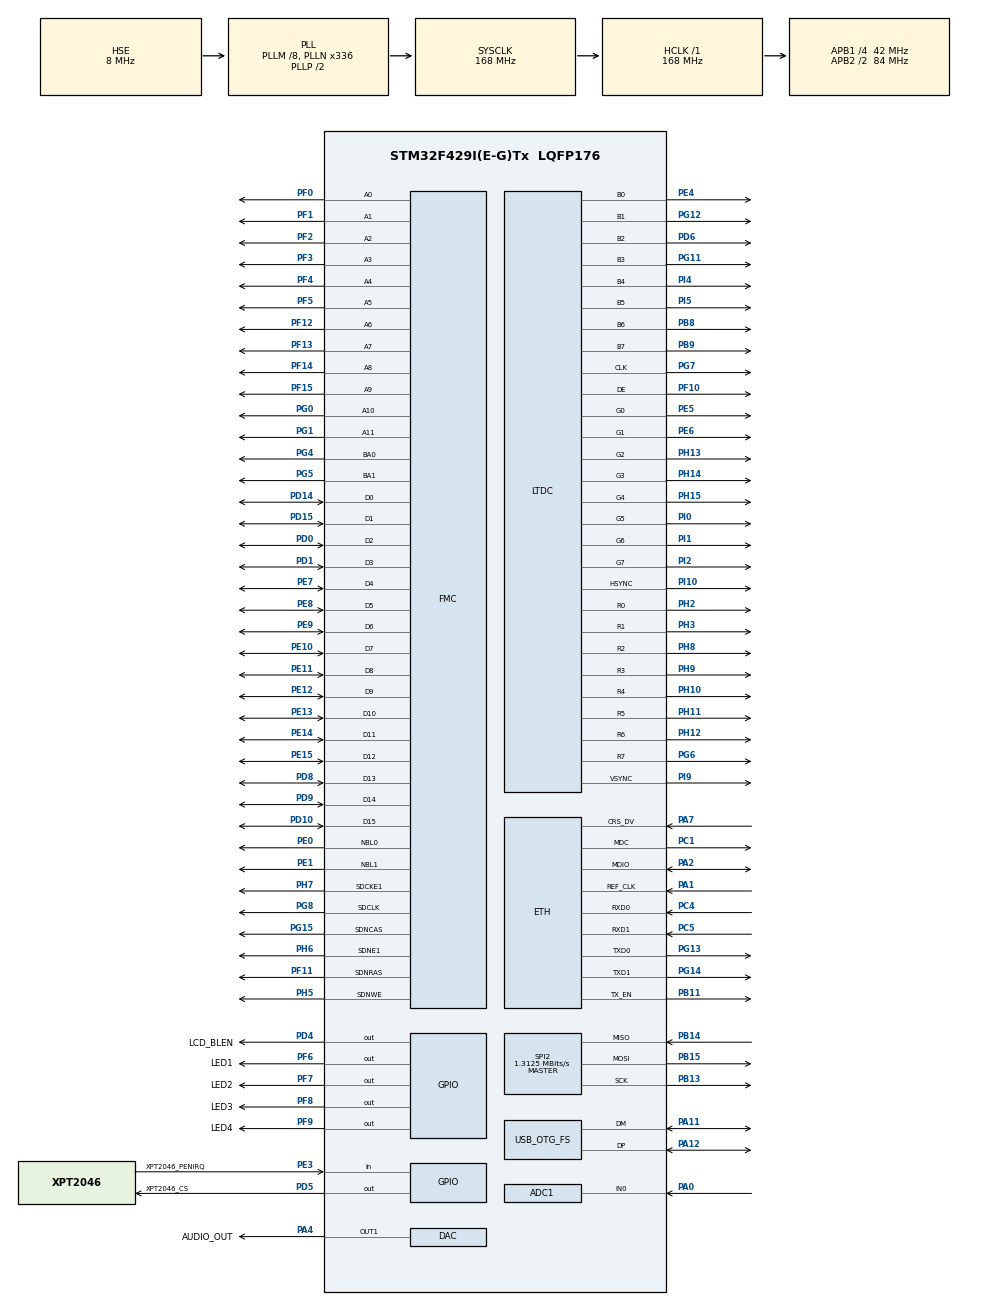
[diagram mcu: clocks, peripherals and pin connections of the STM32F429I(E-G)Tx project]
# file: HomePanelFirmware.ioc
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ADC1.Channel-0\#ChannelRegularConversion=ADC_CHANNEL_0
ADC1.ClockPrescaler=ADC_CLOCK_SYNC_PCLK_DIV4
ADC1.ContinuousConvMode=DISABLE
ADC1.DMAContinuousRequests=ENABLE
ADC1.DataAlign=ADC_DATAALIGN_LEFT
ADC1.DiscontinuousConvMode=DISABLE
ADC1.EOCSelection=ADC_EOC_SEQ_CONV
ADC1.EnableAnalogWatchDog=false
ADC1.ExternalTrigConv=ADC_EXTERNALTRIGCONV_T2_TRGO
ADC1.ExternalTrigConvEdge=ADC_EXTERNALTRIGCONVEDGE_RISING
ADC1.InjNumberOfConversion=0
ADC1.NbrOfConversion=1
ADC1.NbrOfConversionFlag=1
ADC1.Rank-0\#ChannelRegularConversion=1
ADC1.Resolution=ADC_RESOLUTION_12B
ADC1.SamplingTime-0\#ChannelRegularConversion=ADC_SAMPLETIME_15CYCLES
ADC1.ScanConvMode=DISABLE
ADC1.master=1
DAC.DAC_Trigger=DAC_TRIGGER_T2_TRGO
Dma.ADC1.1.Direction=DMA_PERIPH_TO_MEMORY
Dma.ADC1.1.FIFOMode=DMA_FIFOMODE_DISABLE
Dma.ADC1.1.Instance=DMA2_Stream0
Dma.ADC1.1.MemDataAlignment=DMA_MDATAALIGN_HALFWORD
Dma.ADC1.1.MemInc=DMA_MINC_ENABLE
Dma.ADC1.1.Mode=DMA_CIRCULAR
Dma.ADC1.1.PeriphDataAlignment=DMA_PDATAALIGN_HALFWORD
Dma.ADC1.1.PeriphInc=DMA_PINC_DISABLE
Dma.ADC1.1.Priority=DMA_PRIORITY_HIGH
Dma.DAC1.0.Direction=DMA_MEMORY_TO_PERIPH
Dma.DAC1.0.FIFOMode=DMA_FIFOMODE_DISABLE
Dma.DAC1.0.Instance=DMA1_Stream5
Dma.DAC1.0.MemDataAlignment=DMA_MDATAALIGN_HALFWORD
Dma.DAC1.0.MemInc=DMA_MINC_ENABLE
Dma.DAC1.0.Mode=DMA_CIRCULAR
Dma.DAC1.0.PeriphDataAlignment=DMA_PDATAALIGN_HALFWORD
Dma.DAC1.0.PeriphInc=DMA_PINC_DISABLE
Dma.DAC1.0.Priority=DMA_PRIORITY_HIGH
Dma.Request0=DAC1
Dma.Request1=ADC1
ETH.MACAddr=00\:80\:E4\:00\:00\:00
ETH.MediaInterface=ETH_MEDIA_INTERFACE_RMII
ETH.PHY_ISFR=0x0012
ETH.PHY_ISFR_INT4=0x0020
ETH.PHY_Name_RMII=LAN8742A_PHY_ADDRESS
FMC.CASLatency1=FMC_SDRAM_CAS_LATENCY_3
FMC.ExitSelfRefreshDelay1=10
FMC.LoadToActiveDelay1=2
FMC.RCDDelay1=2
FMC.RPDelay1=2
FMC.RPDelay2=2
FMC.ReadBurst1=FMC_SDRAM_RBURST_ENABLE
FMC.ReadBurst2=FMC_SDRAM_RBURST_ENABLE
FMC.ReadPipeDelay1=FMC_SDRAM_RPIPE_DELAY_2
FMC.ReadPipeDelay2=FMC_SDRAM_RPIPE_DELAY_2
FMC.RowCycleDelay1=6
FMC.RowCycleDelay2=6
FMC.SDClockPeriod1=FMC_SDRAM_CLOCK_PERIOD_2
FMC.SDClockPeriod2=FMC_SDRAM_CLOCK_PERIOD_2
FMC.SelfRefreshTime1=7
FMC.WriteRecoveryTime1=5
FREERTOS.Tasks01=defaultTask,0,128,StartDefaultTask,Default,NULL,Dynamic,NULL,NULL
FREERTOS.configGENERATE_RUN_TIME_STATS=0
FREERTOS.configTOTAL_HEAP_SIZE=70000
FREERTOS.configUSE_COUNTING_SEMAPHORES=1
FREERTOS.configUSE_STATS_FORMATTING_FUNCTIONS=1
FREERTOS.configUSE_TIMERS=1
FREERTOS.configUSE_TRACE_FACILITY=1
LTDC.ActiveH=272
LTDC.ActiveW=480
LTDC.Alpha0_L0=255
LTDC.Alpha_L0=255
LTDC.FBStartAdress_L0=0xD0000000
LTDC.Green=255
LTDC.HBP=2
LTDC.HFP=2
LTDC.HSync=41
LTDC.ImageHeight_L0=272
LTDC.ImageWidth_L0=480
LTDC.Layers=0
LTDC.VSync=10
LTDC.WindowX1_L0=480
LTDC.WindowY1_L0=272
LWIP.LWIP_DHCP_CHECK_LINK_UP=1
LWIP.LWIP_IGMP=1
LWIP.LWIP_MULTICAST_TX_OPTIONS=1
LWIP.LWIP_NETIF_API=1
LWIP.LWIP_NETIF_LINK_CALLBACK=1
LWIP.LWIP_NETIF_STATUS_CALLBACK=1
LWIP.LWIP_SO_RCVTIMEO=1
LWIP.LWIP_SO_SNDTIMEO=1
LWIP.LWIP_TCPIP_TIMEOUT=1
LWIP.LWIP_TCP_KEEPALIVE=1
LWIP.MEMP_NUM_NETBUF=4
LWIP.Version=v2.0.0_Cube
MBEDTLS.MBEDTLS_KEY_EXCHANGE_PSK_ENABLED=1
MBEDTLS.MBEDTLS_KEY_EXCHANGE_RSA_ENABLED=1
MBEDTLS.MBEDTLS_KEY_EXCHANGE_RSA_PSK_ENABLED=1
MBEDTLS.MBEDTLS_PKCS1_V15=1
MBEDTLS.MBEDTLS_PKCS1_V21=1
MBEDTLS.MBEDTLS_PKCS5_C=1
MBEDTLS.MBEDTLS_PK_RSA_ALT_SUPPORT=1
MBEDTLS.MBEDTLS_RSA_C=1
MBEDTLS.MBEDTLS_X509_ALLOW_EXTENSIONS_NON_V3=1
MBEDTLS.MBEDTLS_X509_ALLOW_UNSUPPORTED_CRITICAL_EXTENSION=1
MBEDTLS.MBEDTLS_X509_RSASSA_PSS_SUPPORT=1
Mcu.Family=STM32F4
Mcu.Name=STM32F429I(E-G)Tx
Mcu.Package=LQFP176
NVIC.ADC_IRQn=true\:5\:0\:false\:false\:true\:true\:true
NVIC.DMA1_Stream5_IRQn=true\:5\:0\:false\:false\:true\:true\:false
NVIC.DMA2_Stream0_IRQn=true\:5\:0\:false\:false\:true\:true\:false
NVIC.ETH_IRQn=true\:5\:0\:false\:false\:true\:true\:false
NVIC.HASH_RNG_IRQn=true\:5\:0\:false\:false\:true\:true\:true
NVIC.LTDC_ER_IRQn=true\:5\:0\:false\:false\:true\:true\:true
NVIC.LTDC_IRQn=true\:5\:0\:false\:false\:true\:true\:true
NVIC.OTG_FS_IRQn=true\:5\:0\:false\:false\:true\:true\:false
NVIC.PriorityGroup=NVIC_PRIORITYGROUP_4
NVIC.SPI2_IRQn=true\:5\:0\:false\:false\:true\:true\:true
NVIC.TIM2_IRQn=true\:5\:0\:false\:false\:true\:true\:true
NVIC.TIM6_DAC_IRQn=true\:5\:0\:false\:false\:true\:true\:true
PA0/WKUP.Signal=ADCx_IN0
PA1.Mode=RMII
PA1.Signal=ETH_REF_CLK
PA11.Mode=Device_Only
PA11.Signal=USB_OTG_FS_DM
PA12.Mode=Device_Only
PA12.Signal=USB_OTG_FS_DP
PA2.Mode=RMII
PA2.Signal=ETH_MDIO
PA4.GPIO_Label=AUDIO_OUT
PA4.Signal=COMP_DAC1_group
PA7.Mode=RMII
PA7.Signal=ETH_CRS_DV
PB11.Mode=RMII
PB11.Signal=ETH_TX_EN
PB13.Mode=Full_Duplex_Master
PB13.Signal=SPI2_SCK
PB14.Mode=Full_Duplex_Master
PB14.Signal=SPI2_MISO
PB15.Mode=Full_Duplex_Master
PB15.Signal=SPI2_MOSI
PB8.Mode=RGB888
PB8.Signal=LTDC_B6
PB9.Mode=RGB888
PB9.Signal=LTDC_B7
PC1.Mode=RMII
PC1.Signal=ETH_MDC
PC4.Mode=RMII
PC4.Signal=ETH_RXD0
PC5.Mode=RMII
PC5.Signal=ETH_RXD1
PD0.Signal=FMC_D2_DA2
PD1.Signal=FMC_D3_DA3
PD10.Signal=FMC_D15_DA15
PD14.Signal=FMC_D0_DA0
PD15.Signal=FMC_D1_DA1
PD4.GPIO_Label=LCD_BLEN
PD4.Signal=GPIO_Output
PD5.GPIO_Label=XPT2046_CS
PD5.GPIO_PuPd=GPIO_PULLUP
PD5.PinState=GPIO_PIN_SET
PD5.Signal=GPIO_Output
PD6.Mode=RGB888
PD6.Signal=LTDC_B2
PD8.Signal=FMC_D13_DA13
PD9.Signal=FMC_D14_DA14
PE0.Signal=FMC_NBL0
PE1.Signal=FMC_NBL1
PE10.Signal=FMC_D7_DA7
PE11.Signal=FMC_D8_DA8
PE12.Signal=FMC_D9_DA9
PE13.Signal=FMC_D10_DA10
PE14.Signal=FMC_D11_DA11
PE15.Signal=FMC_D12_DA12
PE3.GPIO_Label=XPT2046_PENIRQ
PE3.Signal=GPIO_Input
PE4.Mode=RGB888
PE4.Signal=LTDC_B0
PE5.Mode=RGB888
PE5.Signal=LTDC_G0
PE6.Mode=RGB888
PE6.Signal=LTDC_G1
PE7.Signal=FMC_D4_DA4
PE8.Signal=FMC_D5_DA5
PE9.Signal=FMC_D6_DA6
PF0.Signal=FMC_A0
PF1.Signal=FMC_A1
PF10.Mode=RGB888
PF10.Signal=LTDC_DE
PF11.Signal=FMC_SDNRAS
PF12.Signal=FMC_A6
PF13.Signal=FMC_A7
PF14.Signal=FMC_A8
PF15.Signal=FMC_A9
PF2.Signal=FMC_A2
PF3.Signal=FMC_A3
PF4.Signal=FMC_A4
PF5.Signal=FMC_A5
PF6.GPIO_Label=LED1
PF6.GPIO_ModeDefaultOutputPP=GPIO_MODE_OUTPUT_PP
PF6.GPIO_PuPd=GPIO_NOPULL
PF6.GPIO_Speed=GPIO_SPEED_FREQ_LOW
PF6.PinState=GPIO_PIN_RESET
PF6.Signal=GPIO_Output
PF7.GPIO_Label=LED2
PF7.GPIO_ModeDefaultOutputPP=GPIO_MODE_OUTPUT_PP
PF7.GPIO_PuPd=GPIO_NOPULL
PF7.GPIO_Speed=GPIO_SPEED_FREQ_LOW
PF7.PinState=GPIO_PIN_RESET
PF7.Signal=GPIO_Output
PF8.GPIO_Label=LED3
PF8.GPIO_ModeDefaultOutputPP=GPIO_MODE_OUTPUT_PP
PF8.GPIO_PuPd=GPIO_NOPULL
PF8.GPIO_Speed=GPIO_SPEED_FREQ_LOW
PF8.PinState=GPIO_PIN_RESET
PF8.Signal=GPIO_Output
PF9.GPIO_Label=LED4
PF9.GPIO_ModeDefaultOutputPP=GPIO_MODE_OUTPUT_PP
PF9.GPIO_PuPd=GPIO_NOPULL
PF9.GPIO_Speed=GPIO_SPEED_FREQ_LOW
PF9.PinState=GPIO_PIN_RESET
PF9.Signal=GPIO_Output
PG0.Signal=FMC_A10
PG1.Signal=FMC_A11
PG11.Mode=RGB888
PG11.Signal=LTDC_B3
PG12.Mode=RGB888
PG12.Signal=LTDC_B1
PG13.Mode=RMII
PG13.Signal=ETH_TXD0
PG14.Mode=RMII
PG14.Signal=ETH_TXD1
PG15.Signal=FMC_SDNCAS
PG4.Signal=FMC_A14_BA0
PG5.Signal=FMC_A15_BA1
PG6.Mode=RGB888
PG6.Signal=LTDC_R7
PG7.Mode=RGB888
PG7.Signal=LTDC_CLK
PG8.Signal=FMC_SDCLK
PH0/OSC_IN.Mode=HSE-External-Oscillator
PH0/OSC_IN.Signal=RCC_OSC_IN
PH1/OSC_OUT.Mode=HSE-External-Oscillator
PH1/OSC_OUT.Signal=RCC_OSC_OUT
PH10.Mode=RGB888
PH10.Signal=LTDC_R4
PH11.Mode=RGB888
PH11.Signal=LTDC_R5
PH12.Mode=RGB888
PH12.Signal=LTDC_R6
PH13.Mode=RGB888
PH13.Signal=LTDC_G2
PH14.Mode=RGB888
PH14.Signal=LTDC_G3
PH15.Mode=RGB888
PH15.Signal=LTDC_G4
PH2.Mode=RGB888
PH2.Signal=LTDC_R0
PH3.Mode=RGB888
PH3.Signal=LTDC_R1
PH5.Signal=FMC_SDNWE
PH6.Mode=SdramChipSelect2_1
PH6.Signal=FMC_SDNE1
PH7.Mode=SdramChipSelect2_1
PH7.Signal=FMC_SDCKE1
PH8.Mode=RGB888
PH8.Signal=LTDC_R2
PH9.Mode=RGB888
PH9.Signal=LTDC_R3
PI0.Mode=RGB888
PI0.Signal=LTDC_G5
PI1.Mode=RGB888
PI1.Signal=LTDC_G6
PI10.Mode=RGB888
PI10.Signal=LTDC_HSYNC
PI2.Mode=RGB888
PI2.Signal=LTDC_G7
PI4.Mode=RGB888
PI4.Signal=LTDC_B4
PI5.Mode=RGB888
PI5.Signal=LTDC_B5
PI9.Mode=RGB888
PI9.Signal=LTDC_VSYNC
ProjectManager.HeapSize=0x200
ProjectManager.StackSize=0x400
ProjectManager.TargetToolchain=SW4STM32
RCC.48MHZClocksFreq_Value=48000000
RCC.AHBFreq_Value=168000000
RCC.APB1CLKDivider=RCC_HCLK_DIV4
RCC.APB1Freq_Value=42000000
RCC.APB1TimFreq_Value=84000000
RCC.APB2CLKDivider=RCC_HCLK_DIV2
RCC.APB2Freq_Value=84000000
RCC.APB2TimFreq_Value=168000000
RCC.CortexFreq_Value=168000000
RCC.HCLKFreq_Value=168000000
RCC.HSE_VALUE=8000000
RCC.HSI_VALUE=16000000
RCC.LSE_VALUE=32768
RCC.PLLM=8
RCC.PLLN=336
RCC.PLLQ=7
RCC.PLLSAIDivR=RCC_PLLSAIDIVR_8
RCC.PLLSAIN=160
RCC.SYSCLKFreq_VALUE=168000000
RCC.SYSCLKSource=RCC_SYSCLKSOURCE_PLLCLK
RCC.VCOOutputFreq_Value=336000000
SH.ADCx_IN0.0=ADC1_IN0,IN0
SH.COMP_DAC1_group.0=DAC_OUT1,DAC_OUT1
SH.FMC_A0.0=FMC_A0,12b-sda1
SH.FMC_A1.0=FMC_A1,12b-sda1
SH.FMC_A10.0=FMC_A10,12b-sda1
SH.FMC_A11.0=FMC_A11,12b-sda1
SH.FMC_A14_BA0.0=FMC_BA0,FourSdramBanks1
SH.FMC_A15_BA1.0=FMC_BA1,FourSdramBanks1
SH.FMC_A2.0=FMC_A2,12b-sda1
SH.FMC_A3.0=FMC_A3,12b-sda1
SH.FMC_A4.0=FMC_A4,12b-sda1
SH.FMC_A5.0=FMC_A5,12b-sda1
SH.FMC_A6.0=FMC_A6,12b-sda1
SH.FMC_A7.0=FMC_A7,12b-sda1
SH.FMC_A8.0=FMC_A8,12b-sda1
SH.FMC_A9.0=FMC_A9,12b-sda1
SH.FMC_D0_DA0.0=FMC_D0,sd-16b-d1
SH.FMC_D10_DA10.0=FMC_D10,sd-16b-d1
SH.FMC_D11_DA11.0=FMC_D11,sd-16b-d1
SH.FMC_D12_DA12.0=FMC_D12,sd-16b-d1
SH.FMC_D13_DA13.0=FMC_D13,sd-16b-d1
SH.FMC_D14_DA14.0=FMC_D14,sd-16b-d1
SH.FMC_D15_DA15.0=FMC_D15,sd-16b-d1
SH.FMC_D1_DA1.0=FMC_D1,sd-16b-d1
SH.FMC_D2_DA2.0=FMC_D2,sd-16b-d1
SH.FMC_D3_DA3.0=FMC_D3,sd-16b-d1
SH.FMC_D4_DA4.0=FMC_D4,sd-16b-d1
SH.FMC_D5_DA5.0=FMC_D5,sd-16b-d1
SH.FMC_D6_DA6.0=FMC_D6,sd-16b-d1
SH.FMC_D7_DA7.0=FMC_D7,sd-16b-d1
SH.FMC_D8_DA8.0=FMC_D8,sd-16b-d1
SH.FMC_D9_DA9.0=FMC_D9,sd-16b-d1
SH.FMC_NBL0.0=FMC_NBL0,Sd2ByteEnable1
SH.FMC_NBL1.0=FMC_NBL1,Sd2ByteEnable1
SH.FMC_SDCLK.0=FMC_SDCLK,12b-sda1
SH.FMC_SDNCAS.0=FMC_SDNCAS,12b-sda1
SH.FMC_SDNRAS.0=FMC_SDNRAS,12b-sda1
SH.FMC_SDNWE.0=FMC_SDNWE,12b-sda1
SPI2.BaudRatePrescaler=SPI_BAUDRATEPRESCALER_32
SPI2.CalculateBaudRate=1.3125 MBits/s
SPI2.Direction=SPI_DIRECTION_2LINES
SPI2.Mode=SPI_MODE_MASTER
SPI2.VirtualType=VM_MASTER
TIM2.ClockDivision=TIM_CLOCKDIVISION_DIV1
TIM2.Period=5250
TIM2.TIM_MasterOutputTrigger=TIM_TRGO_UPDATE
TIM6.Period=5250
TIM6.TIM_MasterOutputTrigger=TIM_TRGO_UPDATE
USB_DEVICE.CLASS_NAME_FS=CDC
USB_DEVICE.VirtualMode-CDC_FS=Cdc
USB_DEVICE.VirtualModeFS=Cdc_FS
USB_OTG_FS.VirtualMode=Device_Only
VP_FREERTOS_VS_ENABLE.Mode=Enabled
VP_LWIP_VS_Enabled.Mode=Enabled
VP_MBEDTLS_VS_MBEDTLS.Mode=Enabled
VP_RNG_VS_RNG.Mode=RNG_Activate
VP_RTC_VS_RTC_Activate.Mode=RTC_Enabled
VP_RTC_VS_RTC_Calendar.Mode=RTC_Calendar
VP_TIM2_VS_ClockSourceINT.Mode=Internal
VP_TIM6_VS_ClockSourceINT.Mode=Enable_Timer
VP_USB_DEVICE_VS_USB_DEVICE_CDC_FS.Mode=CDC_FS
board=HomePanelFirmware

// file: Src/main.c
/**
  ******************************************************************************
  * File Name          : main.c
  * Description        : Main program body
  ******************************************************************************
  * This notice applies to any and all portions of this file
  * that are not between comment pairs USER CODE BEGIN and
  * USER CODE END. Other portions of this file, whether
  * inserted by the user or by software development tools
  * are owned by their respective copyright owners.
  *
  * Copyright (c) 2018 STMicroelectronics International N.V.
  * All rights reserved.
  *
  * Redistribution and use in source and binary forms, with or without
  * modification, are permitted, provided that the following conditions are met:
  *
  * 1. Redistribution of source code must retain the above copyright notice,
  *    this list of conditions and the following disclaimer.
  * 2. Redistributions in binary form must reproduce the above copyright notice,
  *    this list of conditions and the following disclaimer in the documentation
  *    and/or other materials provided with the distribution.
  * 3. Neither the name of STMicroelectronics nor the names of other
  *    contributors to this software may be used to endorse or promote products
  *    derived from this software without specific written permission.
  * 4. This software, including modifications and/or derivative works of this
  *    software, must execute solely and exclusively on microcontroller or
  *    microprocessor devices manufactured by or for STMicroelectronics.
  * 5. Redistribution and use of this software other than as permitted under
  *    this license is void and will automatically terminate your rights under
  *    this license.
  *
  * THIS SOFTWARE IS PROVIDED BY STMICROELECTRONICS AND CONTRIBUTORS "AS IS"
  * AND ANY EXPRESS, IMPLIED OR STATUTORY WARRANTIES, INCLUDING, BUT NOT
  * LIMITED TO, THE IMPLIED WARRANTIES OF MERCHANTABILITY, FITNESS FOR A
  * PARTICULAR PURPOSE AND NON-INFRINGEMENT OF THIRD PARTY INTELLECTUAL PROPERTY
  * RIGHTS ARE DISCLAIMED TO THE FULLEST EXTENT PERMITTED BY LAW. IN NO EVENT
  * SHALL STMICROELECTRONICS OR CONTRIBUTORS BE LIABLE FOR ANY DIRECT, INDIRECT,
  * INCIDENTAL, SPECIAL, EXEMPLARY, OR CONSEQUENTIAL DAMAGES (INCLUDING, BUT NOT
  * LIMITED TO, PROCUREMENT OF SUBSTITUTE GOODS OR SERVICES; LOSS OF USE, DATA,
  * OR PROFITS; OR BUSINESS INTERRUPTION) HOWEVER CAUSED AND ON ANY THEORY OF
  * LIABILITY, WHETHER IN CONTRACT, STRICT LIABILITY, OR TORT (INCLUDING
  * NEGLIGENCE OR OTHERWISE) ARISING IN ANY WAY OUT OF THE USE OF THIS SOFTWARE,
  * EVEN IF ADVISED OF THE POSSIBILITY OF SUCH DAMAGE.
  *
  ******************************************************************************
  */

#include "main.h"
#include "stm32f4xx_hal.h"
#include "cmsis_os.h"
#include "adc.h"
#include "dac.h"
#include "dma.h"
#include "ltdc.h"
#include "mbedtls.h"
#include "rng.h"
#include "rtc.h"
#include "spi.h"
#include "tim.h"
#include "usb_device.h"
#include "gpio.h"
#include "fmc.h"

/* USER CODE BEGIN PV */
/* Private variables ---------------------------------------------------------*/

#define SDRAM_MODEREG_BURST_LENGTH_1 0x00
#define SDRAM_MODEREG_BURST_LENGTH_2 0x01
#define SDRAM_MODEREG_BURST_LENGTH_4 0x02
#define SDRAM_MODEREG_BURST_LENGTH_8 0x03

#define SDRAM_MODEREG_BURST_TYPE_SEQUENTIAL			(0x00 << 3)
#define SDRAM_MODEREG_BURST_TYPE_INTERLEAVED		(0x01 << 3)

#define SDRAM_MODEREG_CAS_LATENCY_2					(0x02 << 4)
#define SDRAM_MODEREG_CAS_LATENCY_3					(0x03 << 4)

#define SDRAM_MODEREG_OPERATING_MODE_STANDARD 		0x00

#define SDRAM_MODEREG_WRITEBURST_MODE_PROGRAMMED	(0x00 << 9)
#define SDRAM_MODEREG_WRITEBURST_MODE_SINGLE		(0x01 << 9)

/* USER CODE END PV */

void SystemClock_Config(void);
void MX_FREERTOS_Init(void);

/* USER CODE BEGIN PFP */
/* Private function prototypes -----------------------------------------------*/

/* USER CODE END PFP */

int main(void)
{

  /* MCU Configuration----------------------------------------------------------*/

  /* Reset of all peripherals, Initializes the Flash interface and the Systick. */
  HAL_Init();

  /* Configure the system clock */
  SystemClock_Config();

  /* Initialize all configured peripherals */
  MX_GPIO_Init();
  MX_DMA_Init();
  MX_FMC_Init();
  MX_ADC1_Init();
  MX_RTC_Init();
  MX_TIM2_Init();
  MX_LTDC_Init();
  MX_SPI2_Init();
  MX_RNG_Init();
  MX_TIM6_Init();
  MX_DAC_Init();

  /* USER CODE BEGIN 2 */

	FMC_SDRAM_CommandTypeDef SdramCommand;

	SdramCommand.CommandMode = FMC_SDRAM_CMD_CLK_ENABLE;
	SdramCommand.CommandTarget = FMC_SDRAM_CMD_TARGET_BANK2;
	SdramCommand.AutoRefreshNumber = 1;
	SdramCommand.ModeRegisterDefinition = 0;

	if (HAL_SDRAM_SendCommand(&hsdram1, &SdramCommand, 100) != HAL_OK)
	{
		Error_Handler();
	}

	HAL_Delay(100);

	SdramCommand.CommandMode = FMC_SDRAM_CMD_PALL;
	SdramCommand.CommandTarget = FMC_SDRAM_CMD_TARGET_BANK2;
	SdramCommand.AutoRefreshNumber = 1;
	SdramCommand.ModeRegisterDefinition = 0;

	if (HAL_SDRAM_SendCommand(&hsdram1, &SdramCommand, 100) != HAL_OK)
	{
		Error_Handler();
	}

	SdramCommand.CommandMode = FMC_SDRAM_CMD_AUTOREFRESH_MODE;
	SdramCommand.CommandTarget = FMC_SDRAM_CMD_TARGET_BANK2;
	SdramCommand.AutoRefreshNumber = 4;
	SdramCommand.ModeRegisterDefinition = 0;

	if (HAL_SDRAM_SendCommand(&hsdram1, &SdramCommand, 100) != HAL_OK)
	{
		Error_Handler();
	}

	SdramCommand.CommandMode = FMC_SDRAM_CMD_LOAD_MODE;
	SdramCommand.CommandTarget = FMC_SDRAM_CMD_TARGET_BANK2;
	SdramCommand.AutoRefreshNumber = 1;
	SdramCommand.ModeRegisterDefinition = (uint32_t)
			SDRAM_MODEREG_BURST_LENGTH_1 |
		  SDRAM_MODEREG_BURST_TYPE_SEQUENTIAL |
			SDRAM_MODEREG_CAS_LATENCY_3 |
			SDRAM_MODEREG_OPERATING_MODE_STANDARD |
			SDRAM_MODEREG_WRITEBURST_MODE_SINGLE;

	if (HAL_SDRAM_SendCommand(&hsdram1, &SdramCommand, 100) != HAL_OK)
	{
		Error_Handler();
	}

	if (HAL_SDRAM_ProgramRefreshRate(&hsdram1, 683) != HAL_OK)
	{
		Error_Handler();
	}

  /* USER CODE END 2 */

  /* Call init function for freertos objects (in freertos.c) */
  MX_FREERTOS_Init();

  /* Start scheduler */
  osKernelStart();

  /* We should never get here as control is now taken by the scheduler */

  /* Infinite loop */
  while (1)
  {

  }

}

/** System Clock Configuration
*/
void SystemClock_Config(void)
{

  RCC_OscInitTypeDef RCC_OscInitStruct;
  RCC_ClkInitTypeDef RCC_ClkInitStruct;
  RCC_PeriphCLKInitTypeDef PeriphClkInitStruct;

    /**Configure the main internal regulator output voltage
    */
  __HAL_RCC_PWR_CLK_ENABLE();

  __HAL_PWR_VOLTAGESCALING_CONFIG(PWR_REGULATOR_VOLTAGE_SCALE1);

    /**Initializes the CPU, AHB and APB busses clocks
    */
  RCC_OscInitStruct.OscillatorType = RCC_OSCILLATORTYPE_LSI|RCC_OSCILLATORTYPE_HSE;
  RCC_OscInitStruct.HSEState = RCC_HSE_ON;
  RCC_OscInitStruct.LSIState = RCC_LSI_ON;
  RCC_OscInitStruct.PLL.PLLState = RCC_PLL_ON;
  RCC_OscInitStruct.PLL.PLLSource = RCC_PLLSOURCE_HSE;
  RCC_OscInitStruct.PLL.PLLM = 8;
  RCC_OscInitStruct.PLL.PLLN = 336;
  RCC_OscInitStruct.PLL.PLLP = RCC_PLLP_DIV2;
  RCC_OscInitStruct.PLL.PLLQ = 7;
  if (HAL_RCC_OscConfig(&RCC_OscInitStruct) != HAL_OK)
  {
    _Error_Handler(__FILE__, __LINE__);
  }

    /**Initializes the CPU, AHB and APB busses clocks
    */
  RCC_ClkInitStruct.ClockType = RCC_CLOCKTYPE_HCLK|RCC_CLOCKTYPE_SYSCLK
                              |RCC_CLOCKTYPE_PCLK1|RCC_CLOCKTYPE_PCLK2;
  RCC_ClkInitStruct.SYSCLKSource = RCC_SYSCLKSOURCE_PLLCLK;
  RCC_ClkInitStruct.AHBCLKDivider = RCC_SYSCLK_DIV1;
  RCC_ClkInitStruct.APB1CLKDivider = RCC_HCLK_DIV4;
  RCC_ClkInitStruct.APB2CLKDivider = RCC_HCLK_DIV2;

  if (HAL_RCC_ClockConfig(&RCC_ClkInitStruct, FLASH_LATENCY_5) != HAL_OK)
  {
    _Error_Handler(__FILE__, __LINE__);
  }

  PeriphClkInitStruct.PeriphClockSelection = RCC_PERIPHCLK_LTDC|RCC_PERIPHCLK_RTC;
  PeriphClkInitStruct.PLLSAI.PLLSAIN = 160;
  PeriphClkInitStruct.PLLSAI.PLLSAIR = 2;
  PeriphClkInitStruct.PLLSAIDivR = RCC_PLLSAIDIVR_8;
  PeriphClkInitStruct.RTCClockSelection = RCC_RTCCLKSOURCE_LSI;
  if (HAL_RCCEx_PeriphCLKConfig(&PeriphClkInitStruct) != HAL_OK)
  {
    _Error_Handler(__FILE__, __LINE__);
  }

    /**Configure the Systick interrupt time
    */
  HAL_SYSTICK_Config(HAL_RCC_GetHCLKFreq()/1000);

    /**Configure the Systick
    */
  HAL_SYSTICK_CLKSourceConfig(SYSTICK_CLKSOURCE_HCLK);

  /* SysTick_IRQn interrupt configuration */
  HAL_NVIC_SetPriority(SysTick_IRQn, 15, 0);
}

void _Error_Handler(char * file, int line)
{
  /* USER CODE BEGIN Error_Handler_Debug */
  /* User can add his own implementation to report the HAL error return state */
  while(1)
  {
	  __BKPT();
  }
  /* USER CODE END Error_Handler_Debug */
}

/************************ (C) COPYRIGHT STMicroelectronics *****END OF FILE****/

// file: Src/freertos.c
/**
  ******************************************************************************
  * File Name          : freertos.c
  * Description        : Code for freertos applications
  ******************************************************************************
  * This notice applies to any and all portions of this file
  * that are not between comment pairs USER CODE BEGIN and
  * USER CODE END. Other portions of this file, whether
  * inserted by the user or by software development tools
  * are owned by their respective copyright owners.
  *
  * Copyright (c) 2018 STMicroelectronics International N.V.
  * All rights reserved.
  *
  * Redistribution and use in source and binary forms, with or without
  * modification, are permitted, provided that the following conditions are met:
  *
  * 1. Redistribution of source code must retain the above copyright notice,
  *    this list of conditions and the following disclaimer.
  * 2. Redistributions in binary form must reproduce the above copyright notice,
  *    this list of conditions and the following disclaimer in the documentation
  *    and/or other materials provided with the distribution.
  * 3. Neither the name of STMicroelectronics nor the names of other
  *    contributors to this software may be used to endorse or promote products
  *    derived from this software without specific written permission.
  * 4. This software, including modifications and/or derivative works of this
  *    software, must execute solely and exclusively on microcontroller or
  *    microprocessor devices manufactured by or for STMicroelectronics.
  * 5. Redistribution and use of this software other than as permitted under
  *    this license is void and will automatically terminate your rights under
  *    this license.
  *
  * THIS SOFTWARE IS PROVIDED BY STMICROELECTRONICS AND CONTRIBUTORS "AS IS"
  * AND ANY EXPRESS, IMPLIED OR STATUTORY WARRANTIES, INCLUDING, BUT NOT
  * LIMITED TO, THE IMPLIED WARRANTIES OF MERCHANTABILITY, FITNESS FOR A
  * PARTICULAR PURPOSE AND NON-INFRINGEMENT OF THIRD PARTY INTELLECTUAL PROPERTY
  * RIGHTS ARE DISCLAIMED TO THE FULLEST EXTENT PERMITTED BY LAW. IN NO EVENT
  * SHALL STMICROELECTRONICS OR CONTRIBUTORS BE LIABLE FOR ANY DIRECT, INDIRECT,
  * INCIDENTAL, SPECIAL, EXEMPLARY, OR CONSEQUENTIAL DAMAGES (INCLUDING, BUT NOT
  * LIMITED TO, PROCUREMENT OF SUBSTITUTE GOODS OR SERVICES; LOSS OF USE, DATA,
  * OR PROFITS; OR BUSINESS INTERRUPTION) HOWEVER CAUSED AND ON ANY THEORY OF
  * LIABILITY, WHETHER IN CONTRACT, STRICT LIABILITY, OR TORT (INCLUDING
  * NEGLIGENCE OR OTHERWISE) ARISING IN ANY WAY OUT OF THE USE OF THIS SOFTWARE,
  * EVEN IF ADVISED OF THE POSSIBILITY OF SUCH DAMAGE.
  *
  ******************************************************************************
  */

#include "FreeRTOS.h"
#include "task.h"
#include "cmsis_os.h"

/* USER CODE BEGIN Includes */

#include "adc.h"
#include "gpio.h"
#include "ltdc.h"
#include "tim.h"
#include "thread_client.h"
#include "thread_ui.h"
#include "thread_intercom.h"
#include "gfx.h"

#include <string.h>

/* USER CODE END Includes */

osThreadId defaultTaskHandle;

/* USER CODE BEGIN Variables */

osThreadId clientTaskHandle;
osThreadId uiTaskHandle;
osThreadId intercomTaskHandle;

QueueHandle_t xSampleQueue;
QueueHandle_t xRxBufferQueue;
const int iBufferCount = 4;
const int iBufferSize = 128;

/* USER CODE END Variables */

void StartDefaultTask(void const * argument);

extern void MX_LWIP_Init(void);
extern void MX_USB_DEVICE_Init(void);
extern void MX_MBEDTLS_Init(void);
void MX_FREERTOS_Init(void); /* (MISRA C 2004 rule 8.1) */

/* Hook prototypes */

/* Init FreeRTOS */

void MX_FREERTOS_Init(void) {

  /* Create the thread(s) */
  /* definition and creation of defaultTask */
  osThreadDef(defaultTask, StartDefaultTask, osPriorityNormal, 0, 128);
  defaultTaskHandle = osThreadCreate(osThread(defaultTask), NULL);

}

/* StartDefaultTask function */
void StartDefaultTask(void const * argument)
{
  /* MX_LWIP_Init() is generated within mbedtls_net_init() function in net_cockets.c file */
  /* Up to user to call mbedtls_net_init() function in MBEDTLS initialization step */

  /* init code for USB_DEVICE */
  MX_USB_DEVICE_Init();

  /* Up to user define the empty MX_MBEDTLS_Init() function located in mbedtls.c file */
  MX_MBEDTLS_Init();

  /* USER CODE BEGIN StartDefaultTask */

  memset((void *)0xD0000000, 0xFFFFFFFF, 0x800000);

  HAL_GPIO_WritePin(LCD_BLEN_GPIO_Port, LCD_BLEN_Pin, GPIO_PIN_SET);

  gfxInit();
  ClientThread_Init();
  UserInterfaceThread_Init();
  IntercomThread_Init();

  /* definition and creation of adcSampleTask */
  osThreadDef(clientTask, ClientThread_Main, osPriorityNormal, 0, 2048);
  clientTaskHandle = osThreadCreate(osThread(clientTask), NULL);

  /* definition and creation of adcSampleTask */
  osThreadDef(uiTask, UserInterfaceThread_Main, osPriorityNormal, 0, 512);
  uiTaskHandle = osThreadCreate(osThread(uiTask), NULL);

  /* intercom task */
  osThreadDef(intercomTask, IntercomThread_Main, osPriorityNormal, 0, 1024);
  intercomTaskHandle = osThreadCreate(osThread(intercomTask), NULL);

  /* Infinite loop */
  for(;;)
  {
    osDelay(1);
  }
  /* USER CODE END StartDefaultTask */
}

/************************ (C) COPYRIGHT STMicroelectronics *****END OF FILE****/
